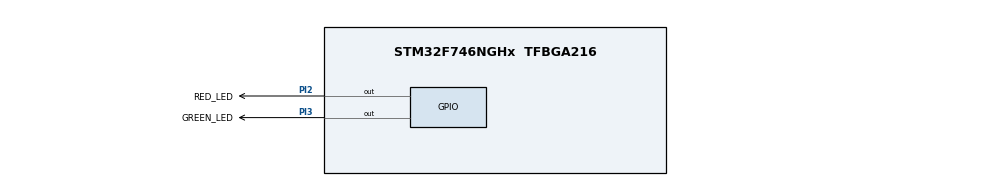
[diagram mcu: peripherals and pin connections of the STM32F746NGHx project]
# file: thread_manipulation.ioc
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FREERTOS.Tasks01=defaultTask,0,128,StartDefaultTask,Default,NULL,Dynamic,NULL,NULL;ThreadRipper1,0,128,StartThreadRipper1,Default,NULL,Dynamic,NULL,NULL;ThreadRipper2,0,128,StartThreadRipper2,Default,NULL,Dynamic,NULL,NULL
Mcu.Family=STM32F7
Mcu.Name=STM32F746NGHx
Mcu.Package=TFBGA216
NVIC.PriorityGroup=NVIC_PRIORITYGROUP_4
NVIC.TIM8_TRG_COM_TIM14_IRQn=true\:0\:0\:false\:false\:true\:false\:false\:true
NVIC.TimeBase=TIM8_TRG_COM_TIM14_IRQn
NVIC.TimeBaseIP=TIM14
PA13.Mode=Serial_Wire
PA13.Signal=SYS_JTMS-SWDIO
PA14.Mode=Serial_Wire
PA14.Signal=SYS_JTCK-SWCLK
PC14/OSC32_IN.Mode=LSE-External-Oscillator
PC14/OSC32_IN.Signal=RCC_OSC32_IN
PC15/OSC32_OUT.Mode=LSE-External-Oscillator
PC15/OSC32_OUT.Signal=RCC_OSC32_OUT
PH0/OSC_IN.Mode=HSE-External-Clock-Source
PH0/OSC_IN.Signal=RCC_OSC_IN
PH1/OSC_OUT.Mode=HSE-External-Clock-Source
PH1/OSC_OUT.Signal=RCC_OSC_OUT
PI2.GPIO_Label=RED_LED
PI2.Signal=GPIO_Output
PI3.GPIO_Label=GREEN_LED
PI3.Signal=GPIO_Output
ProjectManager.HeapSize=0x200
ProjectManager.StackSize=0x400
ProjectManager.TargetToolchain=STM32CubeIDE
RCC.HSE_VALUE=25000000
RCC.HSI_VALUE=16000000
RCC.USBFreq_Value=96000000
RCC.VCOOutputFreq_Value=192000000
VP_FREERTOS_VS_CMSIS_V1.Mode=CMSIS_V1
VP_SYS_VS_tim14.Mode=TIM14
board=STM32F746G-DISCO

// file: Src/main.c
/* USER CODE BEGIN Header */
/**
  ******************************************************************************
  * @file           : main.c
  * @brief          : Main program body
  ******************************************************************************
  * @attention
  *
  * <h2><center>&copy; Copyright (c) 2019 STMicroelectronics.
  * All rights reserved.</center></h2>
  *
  * This software component is licensed by ST under BSD 3-Clause license,
  * the "License"; You may not use this file except in compliance with the
  * License. You may obtain a copy of the License at:
  *                        opensource.org/licenses/BSD-3-Clause
  *
  ******************************************************************************
  */
/* USER CODE END Header */

#include "main.h"
#include "cmsis_os.h"

osThreadId defaultTaskHandle;
osThreadId ThreadRipper1Handle;
osThreadId ThreadRipper2Handle;
/* USER CODE BEGIN PV */
int counter = 0;
/* USER CODE END PV */

void SystemClock_Config(void);
static void MX_GPIO_Init(void);
void StartDefaultTask(void const * argument);
void StartThreadRipper1(void const * argument);
void StartThreadRipper2(void const * argument);

int main(void)
{

  /* MCU Configuration--------------------------------------------------------*/

  /* Reset of all peripherals, Initializes the Flash interface and the Systick. */
  HAL_Init();

  /* Configure the system clock */
  SystemClock_Config();

  /* Initialize all configured peripherals */
  MX_GPIO_Init();

  /* Create the thread(s) */
  /* definition and creation of defaultTask */
  osThreadDef(defaultTask, StartDefaultTask, osPriorityNormal, 0, 128);
  defaultTaskHandle = osThreadCreate(osThread(defaultTask), NULL);

  /* definition and creation of ThreadRipper1 */
  osThreadDef(ThreadRipper1, StartThreadRipper1, osPriorityNormal, 0, 128);
  ThreadRipper1Handle = osThreadCreate(osThread(ThreadRipper1), NULL);

  /* definition and creation of ThreadRipper2 */
  osThreadDef(ThreadRipper2, StartThreadRipper2, osPriorityNormal, 0, 128);
  ThreadRipper2Handle = osThreadCreate(osThread(ThreadRipper2), NULL);

  /* Start scheduler */
  osKernelStart();

  /* We should never get here as control is now taken by the scheduler */

  /* Infinite loop */
  while (1)
  {

  }
}

void SystemClock_Config(void)
{
  RCC_OscInitTypeDef RCC_OscInitStruct = {0};
  RCC_ClkInitTypeDef RCC_ClkInitStruct = {0};

  /** Configure LSE Drive Capability
  */
  HAL_PWR_EnableBkUpAccess();
  /** Configure the main internal regulator output voltage
  */
  __HAL_RCC_PWR_CLK_ENABLE();
  __HAL_PWR_VOLTAGESCALING_CONFIG(PWR_REGULATOR_VOLTAGE_SCALE3);
  /** Initializes the CPU, AHB and APB busses clocks
  */
  RCC_OscInitStruct.OscillatorType = RCC_OSCILLATORTYPE_HSI;
  RCC_OscInitStruct.HSIState = RCC_HSI_ON;
  RCC_OscInitStruct.HSICalibrationValue = RCC_HSICALIBRATION_DEFAULT;
  RCC_OscInitStruct.PLL.PLLState = RCC_PLL_NONE;
  if (HAL_RCC_OscConfig(&RCC_OscInitStruct) != HAL_OK)
  {
    Error_Handler();
  }
  /** Initializes the CPU, AHB and APB busses clocks
  */
  RCC_ClkInitStruct.ClockType = RCC_CLOCKTYPE_HCLK|RCC_CLOCKTYPE_SYSCLK
                              |RCC_CLOCKTYPE_PCLK1|RCC_CLOCKTYPE_PCLK2;
  RCC_ClkInitStruct.SYSCLKSource = RCC_SYSCLKSOURCE_HSI;
  RCC_ClkInitStruct.AHBCLKDivider = RCC_SYSCLK_DIV1;
  RCC_ClkInitStruct.APB1CLKDivider = RCC_HCLK_DIV1;
  RCC_ClkInitStruct.APB2CLKDivider = RCC_HCLK_DIV1;

  if (HAL_RCC_ClockConfig(&RCC_ClkInitStruct, FLASH_LATENCY_0) != HAL_OK)
  {
    Error_Handler();
  }
}

static void MX_GPIO_Init(void)
{
  GPIO_InitTypeDef GPIO_InitStruct = {0};

  /* GPIO Ports Clock Enable */
  __HAL_RCC_GPIOA_CLK_ENABLE();
  __HAL_RCC_GPIOI_CLK_ENABLE();
  __HAL_RCC_GPIOC_CLK_ENABLE();
  __HAL_RCC_GPIOH_CLK_ENABLE();

  /*Configure GPIO pin Output Level */
  HAL_GPIO_WritePin(GPIOI, GREEN_LED_Pin|RED_LED_Pin, GPIO_PIN_RESET);

  /*Configure GPIO pins : GREEN_LED_Pin RED_LED_Pin */
  GPIO_InitStruct.Pin = GREEN_LED_Pin|RED_LED_Pin;
  GPIO_InitStruct.Mode = GPIO_MODE_OUTPUT_PP;
  GPIO_InitStruct.Pull = GPIO_NOPULL;
  GPIO_InitStruct.Speed = GPIO_SPEED_FREQ_LOW;
  HAL_GPIO_Init(GPIOI, &GPIO_InitStruct);

}

void StartDefaultTask(void const * argument)
{

  for(;;)
  {
    osDelay(1);
  }
}

void StartThreadRipper1(void const * argument)
{
  /* USER CODE BEGIN StartThreadRipper1 */
  /* Infinite loop */
  for(;;)
  {
	  for (int i = 0; i < 25; ++i) {
		  HAL_GPIO_TogglePin(GPIOI, GREEN_LED_Pin);
	    osDelay(200);
	}
	  HAL_GPIO_WritePin(GPIOI, GREEN_LED_Pin, GPIO_PIN_RESET);
	  osThreadSuspend(ThreadRipper1Handle);

	  for (int j = 0; j < 5; ++j) {
	 		  HAL_GPIO_TogglePin(GPIOI, GREEN_LED_Pin);
	 	    osDelay(1000);
	 	}
	  HAL_GPIO_WritePin(GPIOI, GREEN_LED_Pin, GPIO_PIN_RESET);
	  osThreadResume(ThreadRipper2Handle);
  }
  /* USER CODE END StartThreadRipper1 */
}

void StartThreadRipper2(void const * argument)
{
  /* USER CODE BEGIN StartThreadRipper2 */
  /* Infinite loop */
  for(;;)
  {
	for(int i = 0; i < 20; i++){
		HAL_GPIO_TogglePin(GPIOI, RED_LED_Pin);
		osDelay(500);
	}
	HAL_GPIO_WritePin(GPIOI, RED_LED_Pin, GPIO_PIN_RESET);
	osThreadResume(ThreadRipper1Handle);
	osThreadSuspend(ThreadRipper2Handle);
  }
  /* USER CODE END StartThreadRipper2 */
}

void HAL_TIM_PeriodElapsedCallback(TIM_HandleTypeDef *htim)
{
  if (htim->Instance == TIM14) {
    HAL_IncTick();
  }
}

void Error_Handler(void)
{
}

/************************ (C) COPYRIGHT STMicroelectronics *****END OF FILE****/
